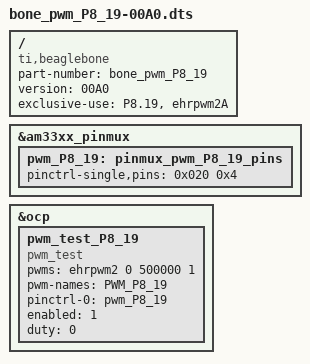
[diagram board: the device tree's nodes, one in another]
/*
 * Copyright (C) 2013 CircuitCo
 * Copyright (C) 2013 Texas Instruments
 *
 * This program is free software; you can redistribute it and/or modify
 * it under the terms of the GNU General Public License version 2 as
 * published by the Free Software Foundation.
 */
/dts-v1/;
/plugin/;

/ {
	compatible = "ti,beaglebone", "ti,beaglebone-black", "ti,beaglebone-green";

	/* identification */
	part-number = "bone_pwm_P8_19";
	version = "00A0";

	/* state the resources this cape uses */
	exclusive-use =
		/* the pin header uses */
		"P8.19",		/* pwm: ehrpwm2A */
		/* the hardware IP uses */
		"ehrpwm2A";

	fragment@0 {
		target = <&am33xx_pinmux>;
		__overlay__ {
			pwm_P8_19: pinmux_pwm_P8_19_pins {
				pinctrl-single,pins = <0x020  0x4>; /* P8_19 (ZCZ ball U10) | MODE 4 */
			};
		};
	};

	fragment@1 {
		target = <&ocp>;
		__overlay__ {
			pwm_test_P8_19 {
				compatible	= "pwm_test";
				pwms 		= <&ehrpwm2 0 500000 1>;
				pwm-names 	= "PWM_P8_19";

				pinctrl-names	= "default";
				pinctrl-0	= <&pwm_P8_19>;

				enabled		= <1>;
				duty		= <0>;
				status 		= "okay";
			};
		};
	};
};
